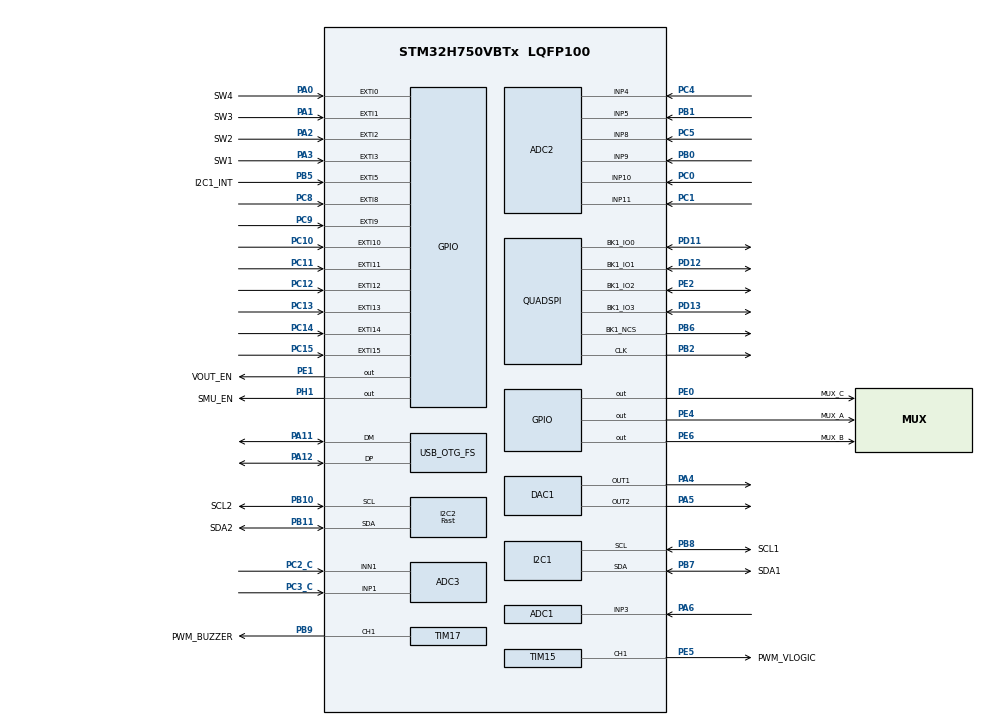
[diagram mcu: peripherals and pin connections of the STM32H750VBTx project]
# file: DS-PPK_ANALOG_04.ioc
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ADC1.Channel-1\#ChannelRegularConversion=ADC_CHANNEL_3
ADC1.ClockPrescaler=ADC_CLOCK_ASYNC_DIV6
ADC1.ClockPrescalerADC3=ADC_CLOCK_ASYNC_DIV6
ADC1.ConversionDataManagement=ADC_CONVERSIONDATA_DMA_CIRCULAR
ADC1.ExternalTrigConv=ADC_EXTERNALTRIG_LPTIM3_OUT
ADC1.NbrOfConversionFlag=1
ADC1.OffsetNumber-1\#ChannelRegularConversion=ADC_OFFSET_NONE
ADC1.OffsetSignedSaturation-1\#ChannelRegularConversion=DISABLE
ADC1.Rank-1\#ChannelRegularConversion=1
ADC1.SamplingTime-1\#ChannelRegularConversion=ADC_SAMPLETIME_32CYCLES_5
ADC1.master=1
ADC2.Channel-0\#ChannelRegularConversion=ADC_CHANNEL_4
ADC2.Channel-1\#ChannelRegularConversion=ADC_CHANNEL_5
ADC2.Channel-2\#ChannelRegularConversion=ADC_CHANNEL_8
ADC2.Channel-3\#ChannelRegularConversion=ADC_CHANNEL_9
ADC2.Channel-4\#ChannelRegularConversion=ADC_CHANNEL_10
ADC2.Channel-5\#ChannelRegularConversion=ADC_CHANNEL_11
ADC2.ClockPrescaler=ADC_CLOCK_ASYNC_DIV6
ADC2.ClockPrescalerADC3=ADC_CLOCK_ASYNC_DIV6
ADC2.ContinuousConvMode=ENABLE
ADC2.ConversionDataManagement=ADC_CONVERSIONDATA_DMA_CIRCULAR
ADC2.NbrOfConversion=6
ADC2.NbrOfConversionFlag=1
ADC2.OffsetNumber-0\#ChannelRegularConversion=ADC_OFFSET_NONE
ADC2.OffsetNumber-1\#ChannelRegularConversion=ADC_OFFSET_NONE
ADC2.OffsetNumber-2\#ChannelRegularConversion=ADC_OFFSET_NONE
ADC2.OffsetNumber-3\#ChannelRegularConversion=ADC_OFFSET_NONE
ADC2.OffsetNumber-4\#ChannelRegularConversion=ADC_OFFSET_NONE
ADC2.OffsetNumber-5\#ChannelRegularConversion=ADC_OFFSET_NONE
ADC2.OffsetSignedSaturation-0\#ChannelRegularConversion=DISABLE
ADC2.OffsetSignedSaturation-1\#ChannelRegularConversion=DISABLE
ADC2.OffsetSignedSaturation-2\#ChannelRegularConversion=DISABLE
ADC2.OffsetSignedSaturation-3\#ChannelRegularConversion=DISABLE
ADC2.OffsetSignedSaturation-4\#ChannelRegularConversion=DISABLE
ADC2.OffsetSignedSaturation-5\#ChannelRegularConversion=DISABLE
ADC2.Overrun=ADC_OVR_DATA_PRESERVED
ADC2.Rank-0\#ChannelRegularConversion=1
ADC2.Rank-1\#ChannelRegularConversion=2
ADC2.Rank-2\#ChannelRegularConversion=3
ADC2.Rank-3\#ChannelRegularConversion=4
ADC2.Rank-4\#ChannelRegularConversion=5
ADC2.Rank-5\#ChannelRegularConversion=6
ADC2.SamplingTime-0\#ChannelRegularConversion=ADC_SAMPLETIME_810CYCLES_5
ADC2.SamplingTime-1\#ChannelRegularConversion=ADC_SAMPLETIME_810CYCLES_5
ADC2.SamplingTime-2\#ChannelRegularConversion=ADC_SAMPLETIME_810CYCLES_5
ADC2.SamplingTime-3\#ChannelRegularConversion=ADC_SAMPLETIME_810CYCLES_5
ADC2.SamplingTime-4\#ChannelRegularConversion=ADC_SAMPLETIME_810CYCLES_5
ADC2.SamplingTime-5\#ChannelRegularConversion=ADC_SAMPLETIME_810CYCLES_5
ADC3.Channel-0\#ChannelRegularConversion=ADC_CHANNEL_1
ADC3.ClockPrescaler=ADC_CLOCK_ASYNC_DIV6
ADC3.ClockPrescalerADC3=ADC_CLOCK_ASYNC_DIV6
ADC3.ConversionDataManagement=ADC_CONVERSIONDATA_DMA_CIRCULAR
ADC3.ExternalTrigConv=ADC_EXTERNALTRIG_LPTIM3_OUT
ADC3.NbrOfConversionFlag=1
ADC3.OffsetNumber-0\#ChannelRegularConversion=ADC_OFFSET_NONE
ADC3.OffsetSignedSaturation-0\#ChannelRegularConversion=DISABLE
ADC3.Rank-0\#ChannelRegularConversion=1
ADC3.SamplingTime-0\#ChannelRegularConversion=ADC_SAMPLETIME_32CYCLES_5
ADC3.SingleDiff-0\#ChannelRegularConversion=ADC_DIFFERENTIAL_ENDED
Bdma.BDMA_GENERATOR0.0.Direction=DMA_PERIPH_TO_MEMORY
Bdma.BDMA_GENERATOR0.0.EventEnable=DISABLE
Bdma.BDMA_GENERATOR0.0.Instance=BDMA_Channel0
Bdma.BDMA_GENERATOR0.0.MemDataAlignment=DMA_MDATAALIGN_HALFWORD
Bdma.BDMA_GENERATOR0.0.MemInc=DMA_MINC_ENABLE
Bdma.BDMA_GENERATOR0.0.Mode=DMA_CIRCULAR
Bdma.BDMA_GENERATOR0.0.PeriphDataAlignment=DMA_PDATAALIGN_WORD
Bdma.BDMA_GENERATOR0.0.PeriphInc=DMA_PINC_DISABLE
Bdma.BDMA_GENERATOR0.0.Polarity=HAL_DMAMUX_REQ_GEN_RISING
Bdma.BDMA_GENERATOR0.0.Priority=DMA_PRIORITY_VERY_HIGH
Bdma.BDMA_GENERATOR0.0.RequestNumber=1
Bdma.BDMA_GENERATOR0.0.SignalID=HAL_DMAMUX2_REQ_GEN_LPTIM3_OUT
Bdma.BDMA_GENERATOR0.0.SyncEnable=DISABLE
Bdma.BDMA_GENERATOR0.0.SyncPolarity=HAL_DMAMUX_SYNC_NO_EVENT
Bdma.BDMA_GENERATOR0.0.SyncRequestNumber=1
Bdma.BDMA_GENERATOR0.0.SyncSignalID=NONE
Bdma.Request0=BDMA_GENERATOR0
Bdma.RequestsNb=1
CORTEX_M7.AccessPermission-Cortex_Memory_Protection_Unit_Region0_Settings=MPU_REGION_FULL_ACCESS
CORTEX_M7.AccessPermission-Cortex_Memory_Protection_Unit_Region1_Settings=MPU_REGION_FULL_ACCESS
CORTEX_M7.AccessPermission-Cortex_Memory_Protection_Unit_Region2_Settings=MPU_REGION_FULL_ACCESS
CORTEX_M7.AccessPermission-Cortex_Memory_Protection_Unit_Region3_Settings=MPU_REGION_FULL_ACCESS
CORTEX_M7.AccessPermission-Cortex_Memory_Protection_Unit_Region4_Settings=MPU_REGION_FULL_ACCESS
CORTEX_M7.AccessPermission-Cortex_Memory_Protection_Unit_Region5_Settings=MPU_REGION_FULL_ACCESS
CORTEX_M7.AccessPermission-Cortex_Memory_Protection_Unit_Region6_Settings=MPU_REGION_FULL_ACCESS
CORTEX_M7.BaseAddress-Cortex_Memory_Protection_Unit_Region0_Settings=0x24000000
CORTEX_M7.BaseAddress-Cortex_Memory_Protection_Unit_Region1_Settings=0x60000000
CORTEX_M7.BaseAddress-Cortex_Memory_Protection_Unit_Region2_Settings=0x30000000
CORTEX_M7.BaseAddress-Cortex_Memory_Protection_Unit_Region3_Settings=0x30020000
CORTEX_M7.BaseAddress-Cortex_Memory_Protection_Unit_Region4_Settings=0x30040000
CORTEX_M7.BaseAddress-Cortex_Memory_Protection_Unit_Region5_Settings=0x38000000
CORTEX_M7.BaseAddress-Cortex_Memory_Protection_Unit_Region6_Settings=0x90000000
CORTEX_M7.CPU_DCache=Enabled
CORTEX_M7.CPU_ICache=Enabled
CORTEX_M7.Enable-Cortex_Memory_Protection_Unit_Region0_Settings=MPU_REGION_ENABLE
CORTEX_M7.Enable-Cortex_Memory_Protection_Unit_Region1_Settings=MPU_REGION_ENABLE
CORTEX_M7.Enable-Cortex_Memory_Protection_Unit_Region2_Settings=MPU_REGION_ENABLE
CORTEX_M7.Enable-Cortex_Memory_Protection_Unit_Region3_Settings=MPU_REGION_ENABLE
CORTEX_M7.Enable-Cortex_Memory_Protection_Unit_Region4_Settings=MPU_REGION_ENABLE
CORTEX_M7.Enable-Cortex_Memory_Protection_Unit_Region5_Settings=MPU_REGION_ENABLE
CORTEX_M7.Enable-Cortex_Memory_Protection_Unit_Region6_Settings=MPU_REGION_ENABLE
CORTEX_M7.IsBufferable-Cortex_Memory_Protection_Unit_Region0_Settings=MPU_ACCESS_BUFFERABLE
CORTEX_M7.IsBufferable-Cortex_Memory_Protection_Unit_Region1_Settings=MPU_ACCESS_BUFFERABLE
CORTEX_M7.IsBufferable-Cortex_Memory_Protection_Unit_Region6_Settings=MPU_ACCESS_BUFFERABLE
CORTEX_M7.IsCacheable-Cortex_Memory_Protection_Unit_Region0_Settings=MPU_ACCESS_CACHEABLE
CORTEX_M7.IsCacheable-Cortex_Memory_Protection_Unit_Region2_Settings=MPU_ACCESS_CACHEABLE
CORTEX_M7.IsCacheable-Cortex_Memory_Protection_Unit_Region3_Settings=MPU_ACCESS_CACHEABLE
CORTEX_M7.IsCacheable-Cortex_Memory_Protection_Unit_Region4_Settings=MPU_ACCESS_CACHEABLE
CORTEX_M7.IsCacheable-Cortex_Memory_Protection_Unit_Region5_Settings=MPU_ACCESS_CACHEABLE
CORTEX_M7.IsCacheable-Cortex_Memory_Protection_Unit_Region6_Settings=MPU_ACCESS_CACHEABLE
CORTEX_M7.MPU_Control=MPU_PRIVILEGED_DEFAULT
CORTEX_M7.Size-Cortex_Memory_Protection_Unit_Region0_Settings=MPU_REGION_SIZE_512KB
CORTEX_M7.Size-Cortex_Memory_Protection_Unit_Region1_Settings=MPU_REGION_SIZE_256MB
CORTEX_M7.Size-Cortex_Memory_Protection_Unit_Region2_Settings=MPU_REGION_SIZE_128KB
CORTEX_M7.Size-Cortex_Memory_Protection_Unit_Region3_Settings=MPU_REGION_SIZE_128KB
CORTEX_M7.Size-Cortex_Memory_Protection_Unit_Region4_Settings=MPU_REGION_SIZE_32KB
CORTEX_M7.Size-Cortex_Memory_Protection_Unit_Region5_Settings=MPU_REGION_SIZE_64KB
CORTEX_M7.Size-Cortex_Memory_Protection_Unit_Region6_Settings=MPU_REGION_SIZE_8MB
CORTEX_M7.TypeExtField-Cortex_Memory_Protection_Unit_Region0_Settings=MPU_TEX_LEVEL1
CORTEX_M7.TypeExtField-Cortex_Memory_Protection_Unit_Region6_Settings=MPU_TEX_LEVEL1
DAC1.DAC1_OutputBuffer-DAC_OUT1=DAC_OUTPUTBUFFER_DISABLE
DAC1.DAC2_OutputBuffer-DAC_OUT2=DAC_OUTPUTBUFFER_DISABLE
DAC1.DAC_Channel-DAC_OUT1=DAC_CHANNEL_1
DAC1.DAC_Channel-DAC_OUT2=DAC_CHANNEL_2
DAC1.DAC_Trigger-DAC_OUT1=DAC_TRIGGER_SOFTWARE
DAC1.DAC_Trigger-DAC_OUT2=DAC_TRIGGER_SOFTWARE
Dma.ADC1.1.Direction=DMA_PERIPH_TO_MEMORY
Dma.ADC1.1.EventEnable=DISABLE
Dma.ADC1.1.FIFOMode=DMA_FIFOMODE_DISABLE
Dma.ADC1.1.Instance=DMA1_Stream0
Dma.ADC1.1.MemDataAlignment=DMA_MDATAALIGN_HALFWORD
Dma.ADC1.1.MemInc=DMA_MINC_ENABLE
Dma.ADC1.1.Mode=DMA_CIRCULAR
Dma.ADC1.1.PeriphDataAlignment=DMA_PDATAALIGN_HALFWORD
Dma.ADC1.1.PeriphInc=DMA_PINC_DISABLE
Dma.ADC1.1.Polarity=HAL_DMAMUX_REQ_GEN_RISING
Dma.ADC1.1.Priority=DMA_PRIORITY_VERY_HIGH
Dma.ADC1.1.RequestNumber=1
Dma.ADC1.1.SignalID=NONE
Dma.ADC1.1.SyncEnable=DISABLE
Dma.ADC1.1.SyncPolarity=HAL_DMAMUX_SYNC_NO_EVENT
Dma.ADC1.1.SyncRequestNumber=1
Dma.ADC1.1.SyncSignalID=NONE
Dma.ADC2.0.Direction=DMA_PERIPH_TO_MEMORY
Dma.ADC2.0.EventEnable=DISABLE
Dma.ADC2.0.FIFOMode=DMA_FIFOMODE_DISABLE
Dma.ADC2.0.Instance=DMA1_Stream1
Dma.ADC2.0.MemDataAlignment=DMA_MDATAALIGN_HALFWORD
Dma.ADC2.0.MemInc=DMA_MINC_ENABLE
Dma.ADC2.0.Mode=DMA_CIRCULAR
Dma.ADC2.0.PeriphDataAlignment=DMA_PDATAALIGN_HALFWORD
Dma.ADC2.0.PeriphInc=DMA_PINC_DISABLE
Dma.ADC2.0.Polarity=HAL_DMAMUX_REQ_GEN_RISING
Dma.ADC2.0.Priority=DMA_PRIORITY_LOW
Dma.ADC2.0.RequestNumber=1
Dma.ADC2.0.SignalID=NONE
Dma.ADC2.0.SyncEnable=DISABLE
Dma.ADC2.0.SyncPolarity=HAL_DMAMUX_SYNC_NO_EVENT
Dma.ADC2.0.SyncRequestNumber=1
Dma.ADC2.0.SyncSignalID=NONE
Dma.ADC3.2.Direction=DMA_PERIPH_TO_MEMORY
Dma.ADC3.2.EventEnable=DISABLE
Dma.ADC3.2.FIFOMode=DMA_FIFOMODE_DISABLE
Dma.ADC3.2.Instance=DMA1_Stream2
Dma.ADC3.2.MemDataAlignment=DMA_MDATAALIGN_HALFWORD
Dma.ADC3.2.MemInc=DMA_MINC_ENABLE
Dma.ADC3.2.Mode=DMA_CIRCULAR
Dma.ADC3.2.PeriphDataAlignment=DMA_PDATAALIGN_HALFWORD
Dma.ADC3.2.PeriphInc=DMA_PINC_DISABLE
Dma.ADC3.2.Polarity=HAL_DMAMUX_REQ_GEN_RISING
Dma.ADC3.2.Priority=DMA_PRIORITY_HIGH
Dma.ADC3.2.RequestNumber=1
Dma.ADC3.2.SignalID=NONE
Dma.ADC3.2.SyncEnable=DISABLE
Dma.ADC3.2.SyncPolarity=HAL_DMAMUX_SYNC_NO_EVENT
Dma.ADC3.2.SyncRequestNumber=1
Dma.ADC3.2.SyncSignalID=NONE
Dma.Request0=ADC2
Dma.Request1=ADC1
Dma.Request2=ADC3
FREERTOS.INCLUDE_vTaskDelayUntil=1
FREERTOS.Tasks01=defaultTask,24,512,StartDefaultTask,Default,NULL,Dynamic,NULL,NULL
FREERTOS.configGENERATE_RUN_TIME_STATS=1
FREERTOS.configMAX_TASK_NAME_LEN=32
FREERTOS.configTOTAL_HEAP_SIZE=32768
FREERTOS.configUSE_NEWLIB_REENTRANT=1
FREERTOS.configUSE_STATS_FORMATTING_FUNCTIONS=1
FREERTOS.copyHeapFile=0
I2C1.Timing=0x10C0ECFF
I2C2.I2C_Speed_Mode=I2C_Fast
I2C2.Timing=0x009034B6
Mcu.Family=STM32H7
Mcu.Name=STM32H750VBTx
Mcu.Package=LQFP100
Mcu.UserConstants=QSPI_FLASH_SIZE_2N_OFFSET,0
NVIC.BDMA_Channel0_IRQn=true\:1\:0\:true\:false\:true\:false\:true\:true\:true
NVIC.DMA1_Stream0_IRQn=true\:1\:0\:true\:false\:true\:false\:false\:true\:true
NVIC.DMA1_Stream1_IRQn=true\:5\:0\:false\:false\:true\:false\:false\:true\:true
NVIC.DMA1_Stream2_IRQn=true\:1\:0\:true\:false\:true\:false\:false\:true\:true
NVIC.DMAMUX2_OVR_IRQn=true\:0\:0\:false\:false\:true\:false\:false\:true\:true
NVIC.EXTI0_IRQn=true\:1\:0\:true\:false\:true\:false\:true\:true\:true
NVIC.EXTI1_IRQn=true\:1\:0\:true\:false\:true\:false\:true\:true\:true
NVIC.EXTI2_IRQn=true\:1\:0\:true\:false\:true\:false\:true\:true\:true
NVIC.EXTI3_IRQn=true\:1\:0\:true\:false\:true\:false\:true\:true\:true
NVIC.OTG_FS_IRQn=true\:5\:0\:false\:false\:true\:true\:false\:true\:true
NVIC.PriorityGroup=NVIC_PRIORITYGROUP_4
NVIC.TIM17_IRQn=true\:5\:0\:false\:false\:true\:true\:true\:true\:true
NVIC.TIM3_IRQn=true\:14\:0\:true\:false\:true\:true\:true\:true\:true
NVIC.TIM6_DAC_IRQn=true\:15\:0\:true\:false\:true\:false\:true\:true\:true
NVIC.TIM7_IRQn=true\:1\:0\:true\:false\:true\:false\:true\:true\:true
NVIC.TimeBase=TIM6_DAC_IRQn
NVIC.TimeBaseIP=TIM6
PA0.GPIO_Label=SW4
PA0.GPIO_ModeDefaultEXTI=GPIO_MODE_IT_RISING_FALLING
PA0.Signal=GPXTI0
PA1.GPIO_Label=SW3
PA1.GPIO_ModeDefaultEXTI=GPIO_MODE_IT_RISING_FALLING
PA1.Signal=GPXTI1
PA11.GPIO_Speed=GPIO_SPEED_FREQ_VERY_HIGH
PA11.Mode=Device_Only
PA11.Signal=USB_OTG_FS_DM
PA12.GPIO_Speed=GPIO_SPEED_FREQ_VERY_HIGH
PA12.Mode=Device_Only
PA12.Signal=USB_OTG_FS_DP
PA13\ (JTMS/SWDIO).Mode=Serial_Wire
PA13\ (JTMS/SWDIO).Signal=DEBUG_JTMS-SWDIO
PA14\ (JTCK/SWCLK).Mode=Serial_Wire
PA14\ (JTCK/SWCLK).Signal=DEBUG_JTCK-SWCLK
PA2.GPIO_Label=SW2
PA2.GPIO_ModeDefaultEXTI=GPIO_MODE_IT_RISING_FALLING
PA2.Signal=GPXTI2
PA3.GPIO_Label=SW1
PA3.GPIO_ModeDefaultEXTI=GPIO_MODE_IT_RISING_FALLING
PA3.Signal=GPXTI3
PA4.Signal=COMP_DAC11_group
PA5.Signal=COMP_DAC12_group
PA6.Signal=ADCx_INP3
PA7.Signal=ADCx_INN3
PB0.Signal=ADCx_INP9
PB1.Signal=ADCx_INP5
PB10.GPIO_Label=SCL2
PB10.Mode=I2C
PB10.Signal=I2C2_SCL
PB11.GPIO_Label=SDA2
PB11.Mode=I2C
PB11.Signal=I2C2_SDA
PB2.Mode=Single Bank 1
PB2.Signal=QUADSPI_CLK
PB5.GPIO_Label=I2C1_INT
PB5.Signal=GPXTI5
PB6.Mode=Single Bank 1
PB6.Signal=QUADSPI_BK1_NCS
PB7.GPIO_Label=SDA1
PB7.Mode=I2C
PB7.Signal=I2C1_SDA
PB8.GPIO_Label=SCL1
PB8.Mode=I2C
PB8.Signal=I2C1_SCL
PB9.GPIO_Label=PWM_BUZZER
PB9.Signal=S_TIM17_CH1
PC0.Signal=ADCx_INP10
PC1.Signal=ADCx_INP11
PC10.GPIO_PuPd=GPIO_NOPULL
PC10.Signal=GPXTI10
PC11.GPIO_PuPd=GPIO_NOPULL
PC11.Signal=GPXTI11
PC12.GPIO_PuPd=GPIO_NOPULL
PC12.Signal=GPXTI12
PC13.GPIO_PuPd=GPIO_NOPULL
PC13.Signal=GPXTI13
PC14-OSC32_IN\ (OSC32_IN).GPIO_PuPd=GPIO_NOPULL
PC14-OSC32_IN\ (OSC32_IN).Signal=GPXTI14
PC15-OSC32_OUT\ (OSC32_OUT).GPIO_PuPd=GPIO_NOPULL
PC15-OSC32_OUT\ (OSC32_OUT).Signal=GPXTI15
PC2_C.Mode=IN1-Differential
PC2_C.Signal=ADC3_INN1
PC3_C.Mode=IN1-Differential
PC3_C.Signal=ADC3_INP1
PC4.Signal=ADCx_INP4
PC5.Signal=ADCx_INP8
PC8.GPIO_PuPd=GPIO_NOPULL
PC8.Signal=GPXTI8
PC9.GPIO_PuPd=GPIO_NOPULL
PC9.Signal=GPXTI9
PD11.Mode=Single Bank 1
PD11.Signal=QUADSPI_BK1_IO0
PD12.Mode=Single Bank 1
PD12.Signal=QUADSPI_BK1_IO1
PD13.Mode=Single Bank 1
PD13.Signal=QUADSPI_BK1_IO3
PE0.GPIO_Label=MUX_C
PE0.GPIO_ModeDefaultOutputPP=GPIO_MODE_OUTPUT_OD
PE0.GPIO_PuPd=GPIO_PULLUP
PE0.PinState=GPIO_PIN_SET
PE0.Signal=GPIO_Output
PE1.GPIO_Label=VOUT_EN
PE1.GPIO_ModeDefaultOutputPP=GPIO_MODE_OUTPUT_PP
PE1.GPIO_PuPd=GPIO_NOPULL
PE1.Signal=GPIO_Output
PE2.Mode=Single Bank 1
PE2.Signal=QUADSPI_BK1_IO2
PE4.GPIO_Label=MUX_A
PE4.GPIO_ModeDefaultOutputPP=GPIO_MODE_OUTPUT_OD
PE4.GPIO_PuPd=GPIO_PULLUP
PE4.PinState=GPIO_PIN_SET
PE4.Signal=GPIO_Output
PE5.GPIO_Label=PWM_VLOGIC
PE5.GPIO_Speed=GPIO_SPEED_FREQ_MEDIUM
PE5.Signal=S_TIM15_CH1
PE6.GPIO_Label=MUX_B
PE6.GPIO_ModeDefaultOutputPP=GPIO_MODE_OUTPUT_OD
PE6.GPIO_PuPd=GPIO_PULLUP
PE6.Signal=GPIO_Output
PH0-OSC_IN\ (PH0).Mode=HSE-External-Clock-Source
PH0-OSC_IN\ (PH0).Signal=RCC_OSC_IN
PH1-OSC_OUT\ (PH1).GPIO_Label=SMU_EN
PH1-OSC_OUT\ (PH1).Signal=GPIO_Output
ProjectManager.HeapSize=0x1000
ProjectManager.StackSize=0x1000
ProjectManager.TargetToolchain=STM32CubeIDE
QUADSPI.ChipSelectHighTime=QSPI_CS_HIGH_TIME_2_CYCLE
QUADSPI.ClockPrescaler=1
QUADSPI.FifoThreshold=32
QUADSPI.FlashSize=QSPI_FLASH_SIZE_2N_OFFSET
QUADSPI.SampleShifting=QSPI_SAMPLE_SHIFTING_HALFCYCLE
RCC.ADCFreq_Value=64000000
RCC.APB1Freq_Value=100000000
RCC.APB2Freq_Value=100000000
RCC.APB3Freq_Value=100000000
RCC.APB4Freq_Value=100000000
RCC.CECCLockSelection=RCC_CECCLKSOURCE_LSI
RCC.CKPERSourceSelection=RCC_CLKPSOURCE_HSE
RCC.CSI_VALUE=4000000
RCC.CortexFreq_Value=400000000
RCC.Cortex_Div=SYSTICK_CLKSOURCE_HCLK
RCC.Cortex_DivARG=SystemCoreClock/1000
RCC.D1PPRE=RCC_APB3_DIV2
RCC.D2PPRE1=RCC_APB1_DIV2
RCC.D2PPRE2=RCC_APB2_DIV2
RCC.D3PPRE=RCC_APB4_DIV2
RCC.DFSDMCLockSelection=RCC_DFSDM1CLKSOURCE_D2PCLK1
RCC.DIVM1=5
RCC.DIVM2=25
RCC.DIVM3=25
RCC.DIVN1=160
RCC.DIVN2=512
RCC.DIVN3=160
RCC.DIVP1=2
RCC.DIVP2=8
RCC.DIVP3=2
RCC.DIVQ1=2
RCC.DIVQ2=2
RCC.DIVR1=2
RCC.DIVR2=2
RCC.DIVR3=25
RCC.DSICLockSelection=RCC_DSICLKSOURCE_PHY
RCC.DSIPHY_Div=8
RCC.DSITX_Div=4
RCC.DSI_PHY_VALUE=12288000
RCC.EXTERNAL_CLOCK_VALUE=12288000
RCC.FDCANCLockSelection=RCC_FDCANCLKSOURCE_PLL
RCC.FMCCLockSelection=RCC_FMCCLKSOURCE_D1HCLK
RCC.HCLKFreq_Value=200000000
RCC.HPRE=RCC_HCLK_DIV2
RCC.HSE_VALUE=25000000
RCC.HSIDiv=RCC_PLLSAIDIVR_1
RCC.HSI_VALUE=64000000
RCC.I2C123CLockSelection=RCC_I2C123CLKSOURCE_D2PCLK1
RCC.I2C4CLockSelection=RCC_I2C4CLKSOURCE_D3PCLK1
RCC.LPTIM1CLockSelection=RCC_LPTIM1CLKSOURCE_PLL3
RCC.LPTIM2CLockSelection=RCC_LPTIM2CLKSOURCE_D3PCLK1
RCC.LPTIM345CLockSelection=RCC_LPTIM345CLKSOURCE_PLL3
RCC.LPUART1CLockSelection=RCC_LPUART1CLKSOURCE_D3PCLK1
RCC.PLL1_VCI_Range-AdvancedSettings=RCC_PLL1VCIRANGE_0
RCC.PLL1_VCO_SEL-AdvancedSettings=RCC_PLL1VCOWIDE
RCC.PLLDSIDev=2
RCC.PLLDSIIDF=DSI_PLL_IN_DIV1
RCC.PLLDSIMult=2
RCC.PLLDSINDIV=20
RCC.PLLDSIODF=DSI_PLL_OUT_DIV1
RCC.PLLSourceVirtual=RCC_PLLSOURCE_HSE
RCC.RC48_VALUE=48000000
RCC.RCC_MCO1Source=RCC_MCO1SOURCE_HSI
RCC.RCC_MCO2Source=RCC_MCO2SOURCE_SYSCLK
RCC.RCC_MCODiv1=RCC_MCODIV_1
RCC.RCC_MCODiv2=RCC_MCODIV_1
RCC.RCC_RTC_Clock_Source_FROM_HSE=RCC_RTCCLKSOURCE_HSE_DIV2
RCC.RNGCLockSelection=RCC_RNGCLKSOURCE_HSI48
RCC.SAI1CLockSelection=RCC_SAI1CLKSOURCE_PLL
RCC.SAI23CLockSelection=RCC_SAI23CLKSOURCE_PLL
RCC.SAI4ACLockSelection=RCC_SAI4ACLKSOURCE_PLL
RCC.SAI4BCLockSelection=RCC_SAI4BCLKSOURCE_PLL
RCC.SPDIFCLockSelection=RCC_SPDIFRXCLKSOURCE_PLL
RCC.SPI123CLockSelection=RCC_SPI123CLKSOURCE_PLL
RCC.SPI6CLockSelection=RCC_SPI6CLKSOURCE_D3PCLK1
RCC.SWPCLockSelection=RCC_SWPMI1CLKSOURCE_D2PCLK1
RCC.SYSCLKFreq_VALUE=400000000
RCC.SYSCLKSource=RCC_SYSCLKSOURCE_PLLCLK
RCC.Spi45ClockSelection=RCC_SPI45CLKSOURCE_D2PCLK1
RCC.USART16CLockSelection=RCC_USART16CLKSOURCE_D2PCLK2
RCC.USART234578CLockSelection=RCC_USART234578CLKSOURCE_D2PCLK1
RCC.USBCLockSelection=RCC_USBCLKSOURCE_HSI48
RCC.USBFreq_Value=48000000
SH.ADCx_INN3.0=ADC1_INN3
SH.ADCx_INP10.0=ADC2_INP10,IN10-Single-Ended
SH.ADCx_INP11.0=ADC2_INP11,IN11-Single-Ended
SH.ADCx_INP3.0=ADC1_INP3,IN3-Single-Ended
SH.ADCx_INP4.0=ADC2_INP4,IN4-Single-Ended
SH.ADCx_INP5.0=ADC2_INP5,IN5-Single-Ended
SH.ADCx_INP8.0=ADC2_INP8,IN8-Single-Ended
SH.ADCx_INP9.0=ADC2_INP9,IN9-Single-Ended
SH.COMP_DAC11_group.0=DAC1_OUT1,DAC_OUT1
SH.COMP_DAC12_group.0=DAC1_OUT2,DAC_OUT2
SH.S_TIM15_CH1.0=TIM15_CH1,PWM Generation1 CH1
SH.S_TIM17_CH1.0=TIM17_CH1,PWM Generation1 CH1
TIM15.AutoReloadPreload=TIM_AUTORELOAD_PRELOAD_ENABLE
TIM15.Channel-PWM\ Generation1\ CH1=TIM_CHANNEL_1
TIM15.Period=256 - 1
TIM15.Prescaler=2 - 1
TIM17.AutoReloadPreload=TIM_AUTORELOAD_PRELOAD_ENABLE
TIM17.Channel=TIM_CHANNEL_1
TIM17.Period=100 - 1
TIM17.Prescaler=500 - 1
TIM2.Prescaler=2000 - 1
TIM3.AutoReloadPreload=TIM_AUTORELOAD_PRELOAD_ENABLE
TIM3.Channel-Output\ Compare1\ No\ Output=TIM_CHANNEL_1
TIM3.Channel-Output\ Compare2\ No\ Output=TIM_CHANNEL_2
TIM3.Channel-Output\ Compare3\ No\ Output=TIM_CHANNEL_3
TIM3.Channel-Output\ Compare4\ No\ Output=TIM_CHANNEL_4
TIM3.OC1Preload=DISABLE
TIM3.OCMode_1=TIM_OCMODE_TOGGLE
TIM3.OCMode_2=TIM_OCMODE_TIMING
TIM3.OCMode_3=TIM_OCMODE_TIMING
TIM3.OCMode_4=TIM_OCMODE_TIMING
TIM7.AutoReloadPreload=TIM_AUTORELOAD_PRELOAD_DISABLE
TIM7.Period=50- 1
TIM7.Prescaler=200 - 1
USB_DEVICE.APP_RX_DATA_SIZE-CDC_FS=2048
USB_DEVICE.APP_TX_DATA_SIZE-CDC_FS=2048
USB_DEVICE.CLASS_NAME_FS=CDC
USB_DEVICE.VirtualMode-CDC_FS=Cdc
USB_DEVICE.VirtualModeFS=Cdc_FS
USB_OTG_FS.VirtualMode=Device_Only
VP_FREERTOS_VS_CMSIS_V2.Mode=CMSIS_V2
VP_LPTIM3_VS_LPTIM_counterModeInternalClock.Mode=Counts__internal_clock_event_00
VP_SYS_VS_tim6.Mode=TIM6
VP_TIM17_VS_ClockSourceINT.Mode=Enable_Timer
VP_TIM17_VS_OPM.Mode=OPM_bit
VP_TIM2_VS_ClockSourceINT.Mode=Internal
VP_TIM3_VS_no_output1.Mode=Output Compare1 No Output
VP_TIM3_VS_no_output2.Mode=Output Compare2 No Output
VP_TIM3_VS_no_output3.Mode=Output Compare3 No Output
VP_TIM3_VS_no_output4.Mode=Output Compare4 No Output
VP_TIM7_VS_ClockSourceINT.Mode=Enable_Timer
VP_USB_DEVICE_VS_USB_DEVICE_CDC_FS.Mode=CDC_FS
VP_VREFBUF_V_VREFBUF.Mode=ExternalMode
board=custom

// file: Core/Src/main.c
/* USER CODE BEGIN Header */
/**
  ******************************************************************************
  * @file           : main.c
  * @brief          : Main program body
  ******************************************************************************
  * @attention
  *
  * <h2><center>&copy; Copyright (c) 2022 STMicroelectronics.
  * All rights reserved.</center></h2>
  *
  * This software component is licensed by ST under BSD 3-Clause license,
  * the "License"; You may not use this file except in compliance with the
  * License. You may obtain a copy of the License at:
  *                        opensource.org/licenses/BSD-3-Clause
  *
  ******************************************************************************
  */
/* USER CODE END Header */
#include "main.h"
#include "cmsis_os.h"
#include "adc.h"
#include "bdma.h"
#include "dac.h"
#include "dma.h"
#include "i2c.h"
#include "lptim.h"
#include "tim.h"
#include "usb_device.h"
#include "gpio.h"

/* USER CODE BEGIN Includes */
#include "usbd_cdc_if.h"
/* USER CODE END Includes */

void SystemClock_Config(void);
void PeriphCommonClock_Config(void);
static void MPU_Config(void);
void MX_FREERTOS_Init(void);

int main(void)
{
  /* USER CODE BEGIN 1 */
//	SCB->VTOR = 0x90000000; /* 设置中断向量表Addr */
  /* USER CODE END 1 */

  /* MPU Configuration--------------------------------------------------------*/
  MPU_Config();

  /* Enable I-Cache---------------------------------------------------------*/
  SCB_EnableICache();

  /* Enable D-Cache---------------------------------------------------------*/
  SCB_EnableDCache();

  /* MCU Configuration--------------------------------------------------------*/

  /* Reset of all peripherals, Initializes the Flash interface and the Systick. */
  HAL_Init();

  /* USER CODE BEGIN Init */
  USB_Status_Init();
  /* USER CODE END Init */

  /* Configure the system clock */
  SystemClock_Config();

/* Configure the peripherals common clocks */
  PeriphCommonClock_Config();

  /* Initialize all configured peripherals */
  MX_GPIO_Init();
  MX_DMA_Init();
  MX_BDMA_Init();
  MX_I2C2_Init();
  MX_ADC2_Init();
  MX_ADC1_Init();
  MX_ADC3_Init();
  MX_I2C1_Init();
  MX_DAC1_Init();
  MX_TIM2_Init();
  MX_TIM15_Init();
  MX_TIM3_Init();
  MX_TIM7_Init();
  MX_LPTIM3_Init();
  MX_TIM17_Init();

  /* Init scheduler */
  osKernelInitialize();  /* Call init function for freertos objects (in freertos.c) */
  MX_FREERTOS_Init();

  /* Start scheduler */
  osKernelStart();

  /* We should never get here as control is now taken by the scheduler */
  /* Infinite loop */
  while (1)
  {

  }
}

void SystemClock_Config(void)
{
  RCC_OscInitTypeDef RCC_OscInitStruct = {0};
  RCC_ClkInitTypeDef RCC_ClkInitStruct = {0};

  /** Supply configuration update enable
  */
  HAL_PWREx_ConfigSupply(PWR_LDO_SUPPLY);

  /** Configure the main internal regulator output voltage
  */
  __HAL_PWR_VOLTAGESCALING_CONFIG(PWR_REGULATOR_VOLTAGE_SCALE1);

  while(!__HAL_PWR_GET_FLAG(PWR_FLAG_VOSRDY)) {}

  /** Macro to configure the PLL clock source
  */
  __HAL_RCC_PLL_PLLSOURCE_CONFIG(RCC_PLLSOURCE_HSE);

  /** Initializes the RCC Oscillators according to the specified parameters
  * in the RCC_OscInitTypeDef structure.
  */
  RCC_OscInitStruct.OscillatorType = RCC_OSCILLATORTYPE_HSI48|RCC_OSCILLATORTYPE_HSE;
  RCC_OscInitStruct.HSEState = RCC_HSE_BYPASS;
  RCC_OscInitStruct.HSI48State = RCC_HSI48_ON;
  RCC_OscInitStruct.PLL.PLLState = RCC_PLL_ON;
  RCC_OscInitStruct.PLL.PLLSource = RCC_PLLSOURCE_HSE;
  RCC_OscInitStruct.PLL.PLLM = 5;
  RCC_OscInitStruct.PLL.PLLN = 160;
  RCC_OscInitStruct.PLL.PLLP = 2;
  RCC_OscInitStruct.PLL.PLLQ = 2;
  RCC_OscInitStruct.PLL.PLLR = 2;
  RCC_OscInitStruct.PLL.PLLRGE = RCC_PLL1VCIRANGE_2;
  RCC_OscInitStruct.PLL.PLLVCOSEL = RCC_PLL1VCOWIDE;
  RCC_OscInitStruct.PLL.PLLFRACN = 0;
  if (HAL_RCC_OscConfig(&RCC_OscInitStruct) != HAL_OK)
  {
    Error_Handler();
  }

  /** Initializes the CPU, AHB and APB buses clocks
  */
  RCC_ClkInitStruct.ClockType = RCC_CLOCKTYPE_HCLK|RCC_CLOCKTYPE_SYSCLK
                              |RCC_CLOCKTYPE_PCLK1|RCC_CLOCKTYPE_PCLK2
                              |RCC_CLOCKTYPE_D3PCLK1|RCC_CLOCKTYPE_D1PCLK1;
  RCC_ClkInitStruct.SYSCLKSource = RCC_SYSCLKSOURCE_PLLCLK;
  RCC_ClkInitStruct.SYSCLKDivider = RCC_SYSCLK_DIV1;
  RCC_ClkInitStruct.AHBCLKDivider = RCC_HCLK_DIV2;
  RCC_ClkInitStruct.APB3CLKDivider = RCC_APB3_DIV2;
  RCC_ClkInitStruct.APB1CLKDivider = RCC_APB1_DIV2;
  RCC_ClkInitStruct.APB2CLKDivider = RCC_APB2_DIV2;
  RCC_ClkInitStruct.APB4CLKDivider = RCC_APB4_DIV2;

  if (HAL_RCC_ClockConfig(&RCC_ClkInitStruct, FLASH_LATENCY_2) != HAL_OK)
  {
    Error_Handler();
  }
}

void PeriphCommonClock_Config(void)
{
  RCC_PeriphCLKInitTypeDef PeriphClkInitStruct = {0};

  /** Initializes the peripherals clock
  */
  PeriphClkInitStruct.PeriphClockSelection = RCC_PERIPHCLK_ADC;
  PeriphClkInitStruct.PLL2.PLL2M = 25;
  PeriphClkInitStruct.PLL2.PLL2N = 512;
  PeriphClkInitStruct.PLL2.PLL2P = 8;
  PeriphClkInitStruct.PLL2.PLL2Q = 2;
  PeriphClkInitStruct.PLL2.PLL2R = 2;
  PeriphClkInitStruct.PLL2.PLL2RGE = RCC_PLL2VCIRANGE_0;
  PeriphClkInitStruct.PLL2.PLL2VCOSEL = RCC_PLL2VCOWIDE;
  PeriphClkInitStruct.PLL2.PLL2FRACN = 0;
  PeriphClkInitStruct.AdcClockSelection = RCC_ADCCLKSOURCE_PLL2;
  if (HAL_RCCEx_PeriphCLKConfig(&PeriphClkInitStruct) != HAL_OK)
  {
    Error_Handler();
  }
}

/* USER CODE BEGIN 4 */
volatile uint8_t tim17_transmissionReceived = 0;
volatile uint32_t ulHighFrequencyTimerTicks = 0UL;  /* FreeRTOS variables for statistical CPU utilization */

void configureTimerForRunTimeStats(void) {
	ulHighFrequencyTimerTicks = 0UL;
}

unsigned long getRunTimeCounterValue(void) {
	return ulHighFrequencyTimerTicks;
}

/* USER CODE END 4 */

/* MPU Configuration */

void MPU_Config(void)
{
  MPU_Region_InitTypeDef MPU_InitStruct = {0};

  /* Disables the MPU */
  HAL_MPU_Disable();

  /** Initializes and configures the Region and the memory to be protected
  */
  MPU_InitStruct.Enable = MPU_REGION_ENABLE;
  MPU_InitStruct.Number = MPU_REGION_NUMBER0;
  MPU_InitStruct.BaseAddress = 0x24000000;
  MPU_InitStruct.Size = MPU_REGION_SIZE_512KB;
  MPU_InitStruct.SubRegionDisable = 0x0;
  MPU_InitStruct.TypeExtField = MPU_TEX_LEVEL1;
  MPU_InitStruct.AccessPermission = MPU_REGION_FULL_ACCESS;
  MPU_InitStruct.DisableExec = MPU_INSTRUCTION_ACCESS_ENABLE;
  MPU_InitStruct.IsShareable = MPU_ACCESS_NOT_SHAREABLE;
  MPU_InitStruct.IsCacheable = MPU_ACCESS_CACHEABLE;
  MPU_InitStruct.IsBufferable = MPU_ACCESS_BUFFERABLE;

  HAL_MPU_ConfigRegion(&MPU_InitStruct);

  /** Initializes and configures the Region and the memory to be protected
  */
  MPU_InitStruct.Number = MPU_REGION_NUMBER1;
  MPU_InitStruct.BaseAddress = 0x60000000;
  MPU_InitStruct.Size = MPU_REGION_SIZE_256MB;
  MPU_InitStruct.TypeExtField = MPU_TEX_LEVEL0;
  MPU_InitStruct.IsCacheable = MPU_ACCESS_NOT_CACHEABLE;

  HAL_MPU_ConfigRegion(&MPU_InitStruct);

  /** Initializes and configures the Region and the memory to be protected
  */
  MPU_InitStruct.Number = MPU_REGION_NUMBER2;
  MPU_InitStruct.BaseAddress = 0x30000000;
  MPU_InitStruct.Size = MPU_REGION_SIZE_128KB;
  MPU_InitStruct.IsCacheable = MPU_ACCESS_CACHEABLE;
  MPU_InitStruct.IsBufferable = MPU_ACCESS_NOT_BUFFERABLE;

  HAL_MPU_ConfigRegion(&MPU_InitStruct);

  /** Initializes and configures the Region and the memory to be protected
  */
  MPU_InitStruct.Number = MPU_REGION_NUMBER3;
  MPU_InitStruct.BaseAddress = 0x30020000;

  HAL_MPU_ConfigRegion(&MPU_InitStruct);

  /** Initializes and configures the Region and the memory to be protected
  */
  MPU_InitStruct.Number = MPU_REGION_NUMBER4;
  MPU_InitStruct.BaseAddress = 0x30040000;
  MPU_InitStruct.Size = MPU_REGION_SIZE_32KB;

  HAL_MPU_ConfigRegion(&MPU_InitStruct);

  /** Initializes and configures the Region and the memory to be protected
  */
  MPU_InitStruct.Number = MPU_REGION_NUMBER5;
  MPU_InitStruct.BaseAddress = 0x38000000;
  MPU_InitStruct.Size = MPU_REGION_SIZE_64KB;

  HAL_MPU_ConfigRegion(&MPU_InitStruct);

  /** Initializes and configures the Region and the memory to be protected
  */
  MPU_InitStruct.Number = MPU_REGION_NUMBER6;
  MPU_InitStruct.BaseAddress = 0x90000000;
  MPU_InitStruct.Size = MPU_REGION_SIZE_8MB;
  MPU_InitStruct.TypeExtField = MPU_TEX_LEVEL1;
  MPU_InitStruct.IsBufferable = MPU_ACCESS_BUFFERABLE;

  HAL_MPU_ConfigRegion(&MPU_InitStruct);
  /* Enables the MPU */
  HAL_MPU_Enable(MPU_PRIVILEGED_DEFAULT);

}

void HAL_TIM_PeriodElapsedCallback(TIM_HandleTypeDef *htim)
{
  /* USER CODE BEGIN Callback 0 */
	if(htim==&htim7) {
		ulHighFrequencyTimerTicks++;
	}
  /* USER CODE END Callback 0 */
  if (htim->Instance == TIM6) {
    HAL_IncTick();
  }
  /* USER CODE BEGIN Callback 1 */
	if(htim==&htim17) {
		tim17_transmissionReceived = !tim17_transmissionReceived;
	}
  /* USER CODE END Callback 1 */
}

void Error_Handler(void)
{
  __disable_irq();
  while (1)
  {
  }
}
